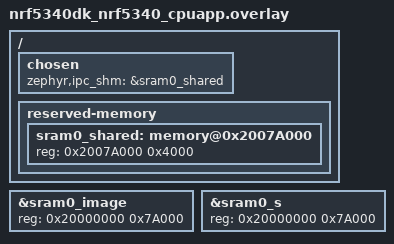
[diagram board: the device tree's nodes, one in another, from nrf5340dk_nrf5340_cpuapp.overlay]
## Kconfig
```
#
# Copyright (c) 2018 Nordic Semiconductor
#
# SPDX-License-Identifier: LicenseRef-Nordic-5-Clause
#

source "Kconfig.zephyr"

config BLE_NETWORK_CORE
	bool "Both BLE host and controller run on network core"
	help
	  Enable the whole BLE stack running on network core
	  
config DFU_EXTERNAL_FLASH
	bool "external flash is used as the secondary slot of MCUBoot"
	default n
	help
		if yes, external flash is used as the secondary slot of MCUBoot
```

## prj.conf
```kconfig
#
# Copyright (c) 2018 Nordic Semiconductor
#
# SPDX-License-Identifier: LicenseRef-Nordic-5-Clause
#

# Enable the UART driver
CONFIG_UART_ASYNC_API=y
CONFIG_NRFX_UARTE0=y
CONFIG_SERIAL=y

CONFIG_GPIO=y

# Make sure printk is not printing to the UART console
CONFIG_CONSOLE=y
CONFIG_UART_CONSOLE=y

CONFIG_HEAP_MEM_POOL_SIZE=12288

CONFIG_FLASH=y
CONFIG_FLASH_PAGE_LAYOUT=y
CONFIG_FLASH_MAP=y
CONFIG_NVS=y
CONFIG_MPU_ALLOW_FLASH_WRITE=y

# Enable DK LED and Buttons library
CONFIG_DK_LIBRARY=y

# This example requires more workqueue stack
CONFIG_SYSTEM_WORKQUEUE_STACK_SIZE=2048

# Config logger
CONFIG_LOG=y
CONFIG_USE_SEGGER_RTT=y
CONFIG_LOG_BACKEND_RTT=y
CONFIG_LOG_BACKEND_UART=n
# CONFIG_LOG_DEFAULT_LEVEL=4

CONFIG_ASSERT=y
# CONFIG_ASSERT_LEVEL=2

CONFIG_SERIAL=y
CONFIG_UART_ASYNC_API=y
CONFIG_NRFX_UARTE1=y
CONFIG_UART_1_NRF_HW_ASYNC=y
CONFIG_UART_1_NRF_HW_ASYNC_TIMER=2
CONFIG_NRFX_UARTE0=y
CONFIG_UART_0_NRF_HW_ASYNC=y
CONFIG_UART_0_NRF_HW_ASYNC_TIMER=1


CONFIG_IPM=y
CONFIG_IPM_NRFX=y
CONFIG_IPM_MSG_CH_1_ENABLE=y
CONFIG_IPM_MSG_CH_1_TX=y
CONFIG_IPM_MSG_CH_0_ENABLE=y
CONFIG_IPM_MSG_CH_0_RX=y
CONFIG_OPENAMP=y
CONFIG_NRF_RPC=y

CONFIG_TINYCBOR=y
CONFIG_RPMSG_MASTER=y
CONFIG_THREAD_CUSTOM_DATA=y
CONFIG_NRF_RPC_CBOR=y
CONFIG_NRF_RPC_THREAD_STACK_SIZE=2048
CONFIG_NRF_RPC_LOG_LEVEL_INF=y

CONFIG_NRF_DFU=y
CONFIG_NRF_DFU_RPC_APP=y
CONFIG_BOOTLOADER_MCUBOOT=y
CONFIG_IMG_MANAGER=y
CONFIG_MCUBOOT_IMG_MANAGER=y
CONFIG_IMG_BLOCK_BUF_SIZE=4096

CONFIG_BLE_NETWORK_CORE=y
CONFIG_NRF53_UPGRADE_NETWORK_CORE=y
CONFIG_BOARD_ENABLE_CPUNET=y

CONFIG_DFU_EXTERNAL_FLASH=y
CONFIG_PM_EXTERNAL_FLASH=y
CONFIG_PM_EXTERNAL_FLASH_DEV_NAME="MX25R64"
CONFIG_PM_EXTERNAL_FLASH_BASE=0x0
CONFIG_PM_EXTERNAL_FLASH_SIZE=0x800000

CONFIG_NORDIC_QSPI_NOR=y
CONFIG_NORDIC_QSPI_NOR_FLASH_LAYOUT_PAGE_SIZE=4096
CONFIG_NORDIC_QSPI_NOR_STACK_WRITE_BUFFER_SIZE=16

CONFIG_PM_PARTITION_SIZE_SETTINGS_STORAGE=0x4000
```

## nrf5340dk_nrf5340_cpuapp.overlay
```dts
/* overlay file for app core */

/* adjust the RAM size of application image */
&sram0_image{
	reg = < 0x20000000 0x7A000 >;
};

&sram0_s{
	reg = < 0x20000000 0x7A000 >;
};

/delete-node/ &sram0_shared;

/ {
	chosen {
		/* shared memory reserved for the inter-processor communication */
		zephyr,ipc_shm = &sram0_shared;
	};

	reserved-memory {
		#address-cells = <1>;
		#size-cells = <1>;
		ranges;	
		sram0_shared: memory@0x2007A000 {
			/* SRAM allocated to shared memory */
			reg = <0x2007A000 0x4000>;
		};
	};
};
```

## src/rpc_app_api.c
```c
/*
 * Copyright (c) 2020 Nordic Semiconductor ASA
 *
 * SPDX-License-Identifier: LicenseRef-BSD-5-Clause-Nordic
 */

#include <zephyr.h>
#include <device.h>
#include <devicetree.h>
#include <drivers/gpio.h>
#include <stdio.h>
#include "rpc_app_api.h"
#include "nrf_rpc_tr.h"
#include <logging/log.h>
#include <drivers/uart.h>
#include "../../common_ids.h"

#define LOG_MODULE_NAME rpc_app_api
LOG_MODULE_REGISTER(LOG_MODULE_NAME);

uint8_t bt_addr[6];
static bool m_connected = false;

int app2net_send_nus(uint8_t *data, uint16_t len)
{
	return rpc_app2net_send(APP2NET_BT_NUS_SEND, data, len);
}


int net2app_receive_bt_addr(uint8_t *buf, uint16_t len)
{	
	memcpy(bt_addr, &buf[1], 6);
	
	LOG_HEXDUMP_INF(&buf[1], 6, "===bt dev addr: ===");
	LOG_INF("addr type %d", buf[0]);

	return 0;
}

#ifdef CONFIG_EXAMPLE_HS_UART
extern int my_uart_send(const uint8_t *buf, size_t len);
#endif

int net2app_receive_nus(uint8_t *buf, uint16_t len)
{
	LOG_HEXDUMP_INF(buf, len, "===nus data: ===");

#ifdef CONFIG_EXAMPLE_HS_UART
	my_uart_send(buf, len);
#endif	
	return 0;
}

int net2app_receive_conn_status(uint8_t *data, uint16_t len)
{
	if (data[0] == 1)
	{
		m_connected = true;
	}
	else
	{
		m_connected = false;
	}

	return 0;
}

bool is_ble_connected(void)
{
	return m_connected;
}

int net2app_receive(int type, uint8_t *data, size_t len)
{
	int err = 0; 

	switch (type)
	{
		case NET2APP_BT_ADDR_SEND:
			err = net2app_receive_bt_addr(data, len);
			break;
		case NET2APP_BT_NUS_RECV:
			err = net2app_receive_nus(data, len);
			break;
		case NET2APP_BT_CONN_STATUS:
			err = net2app_receive_conn_status(data, len);
			break;			
		default:
			break;
	}

	return err;	
}
```
